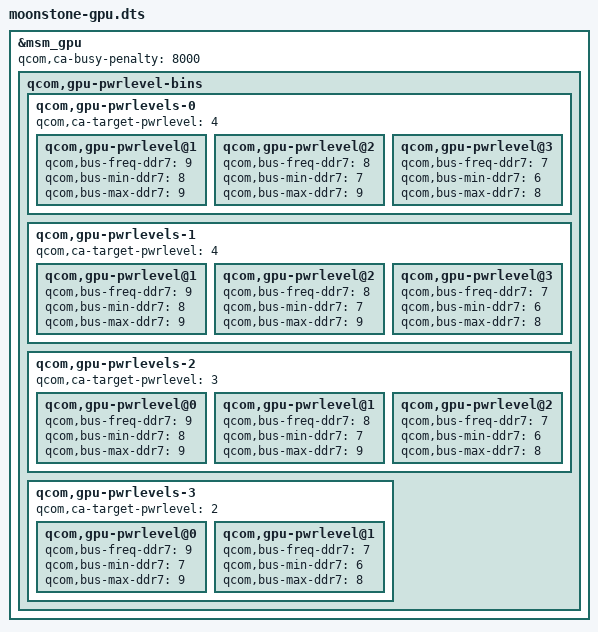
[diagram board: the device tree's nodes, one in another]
&msm_gpu {
    qcom,ca-busy-penalty = <8000>;

    qcom,gpu-pwrlevel-bins {
        qcom,gpu-pwrlevels-0 {
            qcom,ca-target-pwrlevel = <4>;

            qcom,gpu-pwrlevel@1 {
                qcom,bus-freq-ddr7 = <9>;
                qcom,bus-min-ddr7 = <8>;
                qcom,bus-max-ddr7 = <9>;
            };
            qcom,gpu-pwrlevel@2 {
                qcom,bus-freq-ddr7 = <8>;
                qcom,bus-min-ddr7 = <7>;
                qcom,bus-max-ddr7 = <9>;
            };
            qcom,gpu-pwrlevel@3 {
                qcom,bus-freq-ddr7 = <7>;
                qcom,bus-min-ddr7 = <6>;
                qcom,bus-max-ddr7 = <8>;
            };
        };

        qcom,gpu-pwrlevels-1 {
            qcom,ca-target-pwrlevel = <4>;

            qcom,gpu-pwrlevel@1 {
                qcom,bus-freq-ddr7 = <9>;
                qcom,bus-min-ddr7 = <8>;
                qcom,bus-max-ddr7 = <9>;
            };
            qcom,gpu-pwrlevel@2 {
                qcom,bus-freq-ddr7 = <8>;
                qcom,bus-min-ddr7 = <7>;
                qcom,bus-max-ddr7 = <9>;
            };
            qcom,gpu-pwrlevel@3 {
                qcom,bus-freq-ddr7 = <7>;
                qcom,bus-min-ddr7 = <6>;
                qcom,bus-max-ddr7 = <8>;
            };
        };

        qcom,gpu-pwrlevels-2 {
            qcom,ca-target-pwrlevel = <3>;

            qcom,gpu-pwrlevel@0 {
                qcom,bus-freq-ddr7 = <9>;
                qcom,bus-min-ddr7 = <8>;
                qcom,bus-max-ddr7 = <9>;
            };
            qcom,gpu-pwrlevel@1 {
                qcom,bus-freq-ddr7 = <8>;
                qcom,bus-min-ddr7 = <7>;
                qcom,bus-max-ddr7 = <9>;
            };
            qcom,gpu-pwrlevel@2 {
                qcom,bus-freq-ddr7 = <7>;
                qcom,bus-min-ddr7 = <6>;
                qcom,bus-max-ddr7 = <8>;
            };
        };

        qcom,gpu-pwrlevels-3 {
            qcom,ca-target-pwrlevel = <2>;

            qcom,gpu-pwrlevel@0 {
                qcom,bus-freq-ddr7 = <9>;
                qcom,bus-min-ddr7 = <7>;
                qcom,bus-max-ddr7 = <9>;
            };
            qcom,gpu-pwrlevel@1 {
                qcom,bus-freq-ddr7 = <7>;
                qcom,bus-min-ddr7 = <6>;
                qcom,bus-max-ddr7 = <8>;
            };
        };
    };
};
